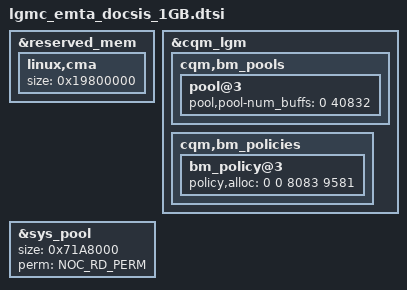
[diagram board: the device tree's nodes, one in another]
// SPDX-License-Identifier: GPL-2.0
/*
 * Copyright (C) 2023 MaxLinear, Inc.
 *
 * This program is free software; you can redistribute it and/or modify it
 * under the terms of the GNU General Public License, as published by the Free
 * Software Foundation; either version 2 of the License, or (at your option)
 * any later version.
 *
 * This program is distributed in the hope that it will be useful, but WITHOUT
 * ANY WARRANTY; without even the implied warranty of MERCHANTABILITY or
 * FITNESS FOR A PARTICULAR PURPOSE.
 * See the GNU General Public License for more details.
 *
 * You should have received a copy of the GNU General Public License along
 * with this program; if not, see <http://www.gnu.org/licenses/>.
 */
&reserved_mem {
	linux,cma {
		size = <0x19800000>;
	};
};

&cqm_lgm {
	/delete-node/ mxl,wav-port-resv;
	cqm,bm_pools {
		pool@3 {
			pool,pool-num_buffs = <0 40832>;
		};
	};
	cqm,bm_policies {
		/delete-node/ bm_policy@6;
		/delete-node/ bm_policy@7;
		/delete-node/ bm_policy@8;
		/delete-node/ bm_policy@9;
		/delete-node/ bm_policy@10;
		/delete-node/ bm_policy@11;
		/delete-node/ bm_policy@12;
		/delete-node/ bm_policy@13;
		/delete-node/ bm_policy@14;
		/delete-node/ bm_policy@15;
		/delete-node/ bm_policy@16;
		/delete-node/ bm_policy@22;
		/delete-node/ bm_policy@23;
		bm_policy@3 {
			policy,alloc = <0 0 8083 9581>;
		};
	};
};

&sys_pool {
	size = <0x71A8000>;
	perm = <NOC_RD_PERM>;
};
